# TC37X register map
File version: 1.0.0
CPU: CM4 r0p1, little endian, MPU, FPU, VTOR, 3 interrupt priority bits
Registers are 16-bit, read-write, reset 0x0 unless marked. A register's access mark holds for its fields unless they carry their own. Offsets are from the block's base; [hi:lo] are bit positions; {n}, {i} and the like mark numbered series; 'fields as' and 'values as' point back to an identical list.

## SRC — ce_src
Base 0xF0038000
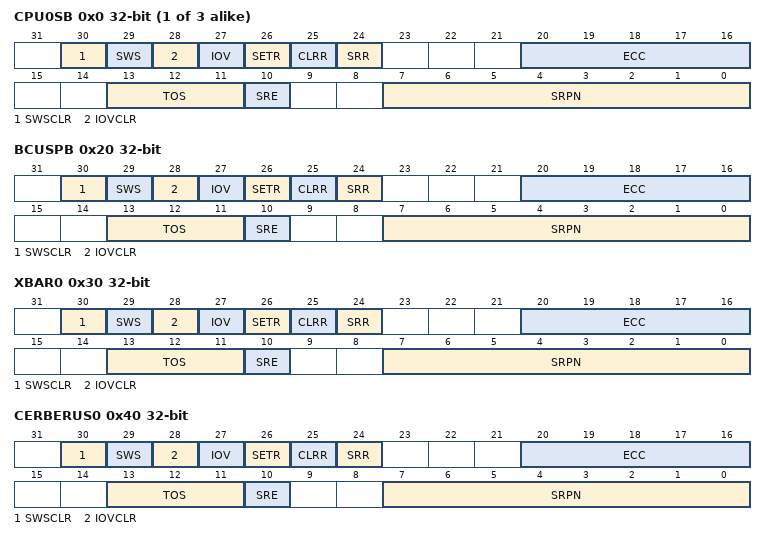
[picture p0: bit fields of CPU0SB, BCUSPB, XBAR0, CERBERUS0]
{0x0+4i} CPU{i}SB 32-bit (i=0..2) — CPU{i} Software Breakpoint Service Request
  [30] SWSCLR wo — SW Sticky Clear Bit
  [29] SWS ro — SW Sticky Bit
  [28] IOVCLR wo — Interrupt Trigger Overflow Clear Bit
  [27] IOV ro — Interrupt Trigger Overflow Bit
  [26] SETR wo — Request Set Bit
  [25] CLRR wo — Request Clear Bit
  [24] SRR ro — Service Request Flag
  [20:16] ECC — Error Correction Code
  [13:11] TOS — Type of Service Control
  [10] SRE — Service Request Enable
  [7:0] SRPN — Service Request Priority Number
0x20 BCUSPB 32-bit — SBCU Service Request (SPB Bus Control Unit)
  fields as CPU0SB
0x30 XBAR0 32-bit — SRI Domain 0 Service Request
  fields as CPU0SB
0x40 CERBERUS0 32-bit — Cerberus Service Request 0
  fields as CPU0SB
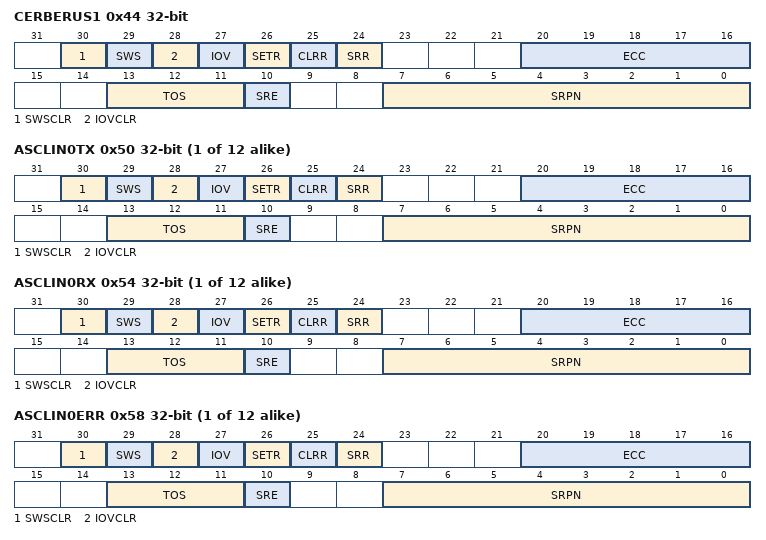
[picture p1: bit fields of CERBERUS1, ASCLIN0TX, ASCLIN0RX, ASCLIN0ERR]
0x44 CERBERUS1 32-bit — Cerberus Service Request 1
  fields as CPU0SB
{0x50+0xC*i} ASCLIN{i}TX 32-bit (i=0..11) — ASCLIN{i} Transmit Service Request
  fields as CPU0SB
{0x54+0xC*i} ASCLIN{i}RX 32-bit (i=0..11) — ASCLIN{i} Receive Service Request
  fields as CPU0SB
{0x58+0xC*i} ASCLIN{i}ERR 32-bit (i=0..11) — ASCLIN{i} Error Service Request
  fields as CPU0SB
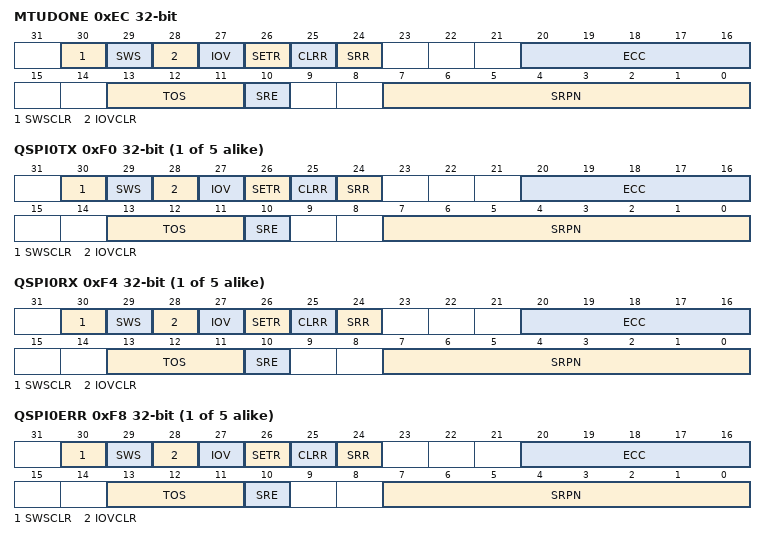
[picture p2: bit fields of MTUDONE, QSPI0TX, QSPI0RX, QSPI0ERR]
0xEC MTUDONE 32-bit — MTU Done Service Request
  fields as CPU0SB
{0xF0+0x14*i} QSPI{i}TX 32-bit (i=0..4) — QSPI{i} Transmit Service Request
  fields as CPU0SB
{0xF4+0x14*i} QSPI{i}RX 32-bit (i=0..4) — QSPI{i} Receive Service Request
  fields as CPU0SB
{0xF8+0x14*i} QSPI{i}ERR 32-bit (i=0..4) — QSPI{i} Error Service Request
  fields as CPU0SB
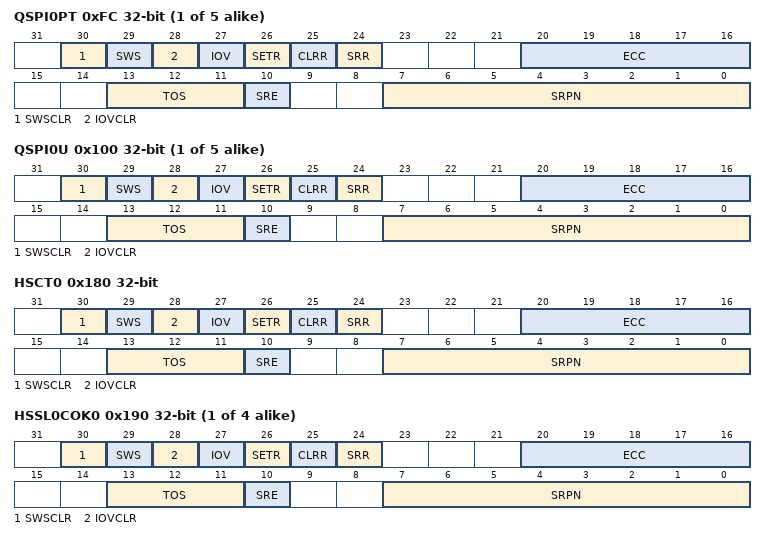
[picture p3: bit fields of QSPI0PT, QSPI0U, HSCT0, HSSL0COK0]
{0xFC+0x14*i} QSPI{i}PT 32-bit (i=0..4) — QSPI{i} Phase Transition Service Request
  fields as CPU0SB
{0x100+0x14*i} QSPI{i}U 32-bit (i=0..4) — QSPI{i} User Defined Service Request
  fields as CPU0SB
0x180 HSCT0 32-bit — HSCT0 Service Request
  fields as CPU0SB
{0x190+0x10*i} HSSL0COK{i} 32-bit (i=0..3) — HSSL0 Channel {i} OK Service Request
  fields as CPU0SB
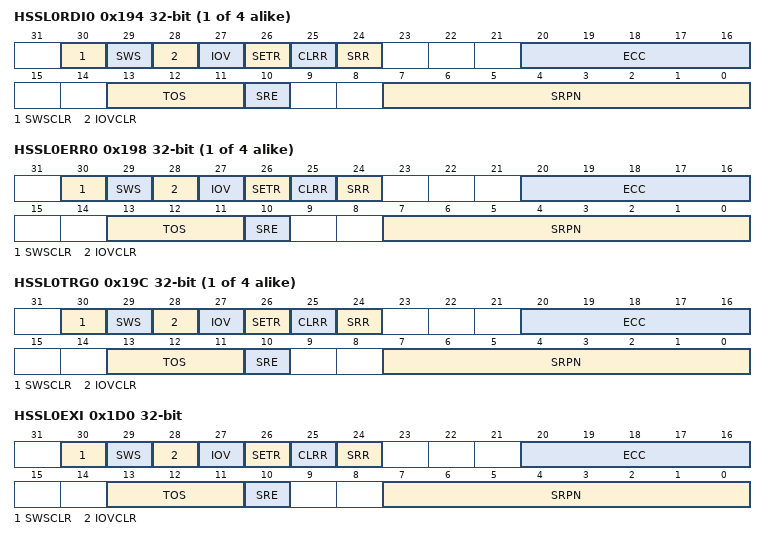
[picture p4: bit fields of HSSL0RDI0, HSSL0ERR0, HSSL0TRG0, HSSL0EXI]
{0x194+0x10*i} HSSL0RDI{i} 32-bit (i=0..3) — HSSL0 Channel {i} Read Data Service Request
  fields as CPU0SB
{0x198+0x10*i} HSSL0ERR{i} 32-bit (i=0..3) — HSSL0 Channel {i} Error Service Request
  fields as CPU0SB
{0x19C+0x10*i} HSSL0TRG{i} 32-bit (i=0..3) — HSSL0 Channel {i} Trigger Interrupt Service Request
  fields as CPU0SB
0x1D0 HSSL0EXI 32-bit — HSSL0 Exception Service Request
  fields as CPU0SB
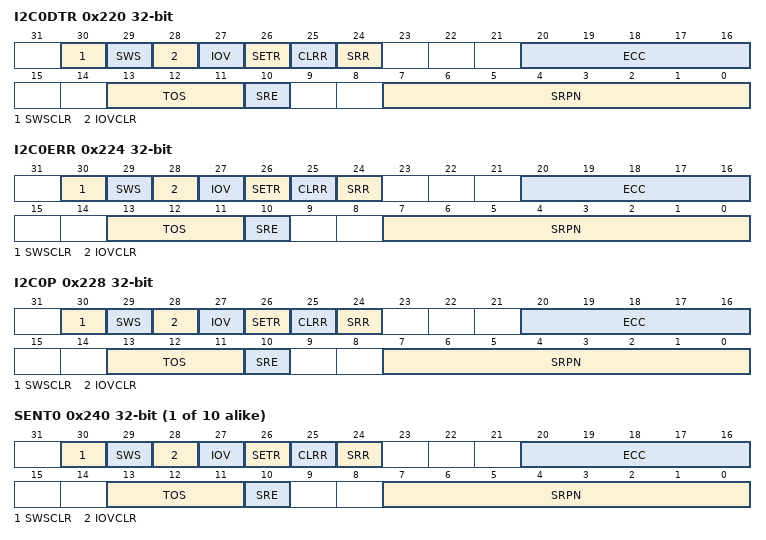
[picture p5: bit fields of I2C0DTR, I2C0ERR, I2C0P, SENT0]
0x220 I2C0DTR 32-bit — I2C0 Data Transfer Request
  fields as CPU0SB
0x224 I2C0ERR 32-bit — I2C0 Error Service Request
  fields as CPU0SB
0x228 I2C0P 32-bit — I2C0 Protocol Service Request
  fields as CPU0SB
{0x240+4i} SENT{i} 32-bit (i=0..9) — SENT TRIG{i} Service Request
  fields as CPU0SB
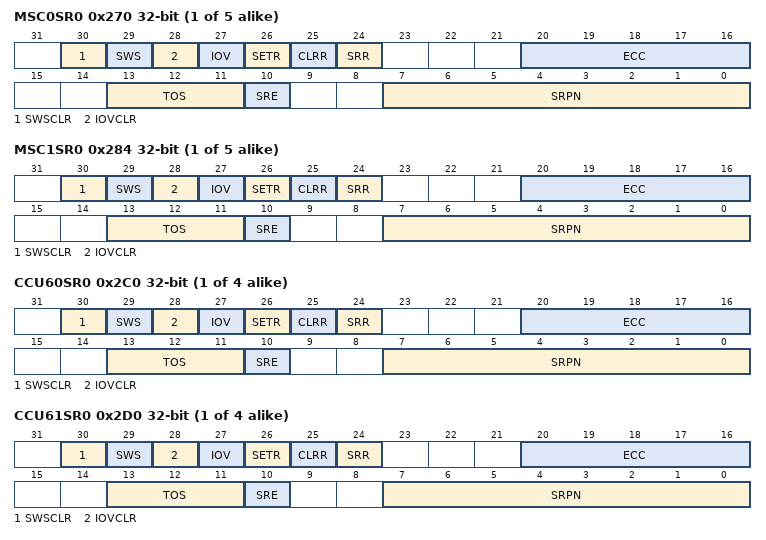
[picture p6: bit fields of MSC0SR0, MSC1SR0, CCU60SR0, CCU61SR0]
{0x270+4i} MSC0SR{i} 32-bit (i=0..4) — MSC0 Service Request {i}
  fields as CPU0SB
{0x284+4i} MSC1SR{i} 32-bit (i=0..4) — MSC1 Service Request {i}
  fields as CPU0SB
{0x2C0+4i} CCU60SR{i} 32-bit (i=0..3) — CCU0 Service Request {i}
  fields as CPU0SB
{0x2D0+4i} CCU61SR{i} 32-bit (i=0..3) — CCU1 Service Request {i}
  fields as CPU0SB
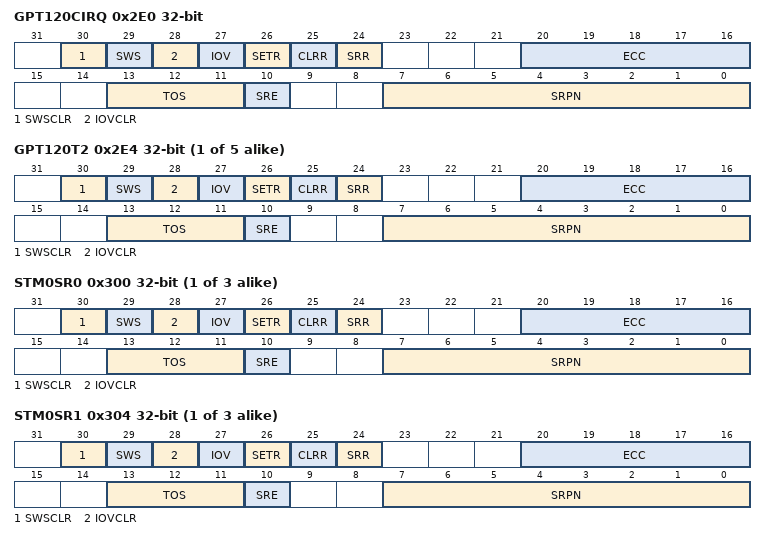
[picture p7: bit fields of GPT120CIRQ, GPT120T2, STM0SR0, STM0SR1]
0x2E0 GPT120CIRQ 32-bit — GPT120 CAPREL Service Request
  fields as CPU0SB
{0x2DC+4i} GPT120T{i} 32-bit (i=2..6) — GPT120 Timer {i} Service Request
  fields as CPU0SB
{0x300+8i} STM{i}SR0 32-bit (i=0..2) — System Timer {i} Service Request 0
  fields as CPU0SB
{0x304+8i} STM{i}SR1 32-bit (i=0..2) — System Timer {i} Service Request 1
  fields as CPU0SB
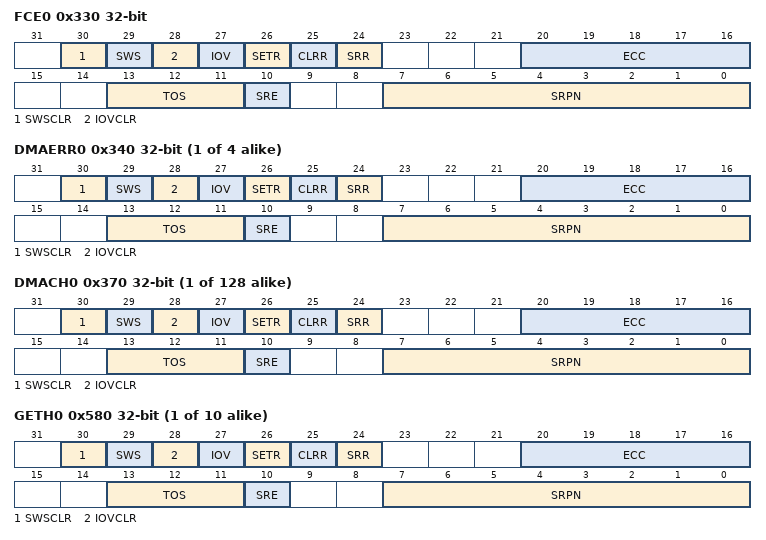
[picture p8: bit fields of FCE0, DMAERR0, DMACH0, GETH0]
0x330 FCE0 32-bit — FCE0 Error Service Request
  fields as CPU0SB
{0x340+4i} DMAERR{i} 32-bit (i=0..3) — DMA Error Service Request {i}
  fields as CPU0SB
{0x370+4i} DMACH{i} 32-bit (i=0..127) — DMA Channel {i} Service Request
  fields as CPU0SB
{0x580+4i} GETH{i} 32-bit (i=0..9) — GETH Service Request {i}
  fields as CPU0SB
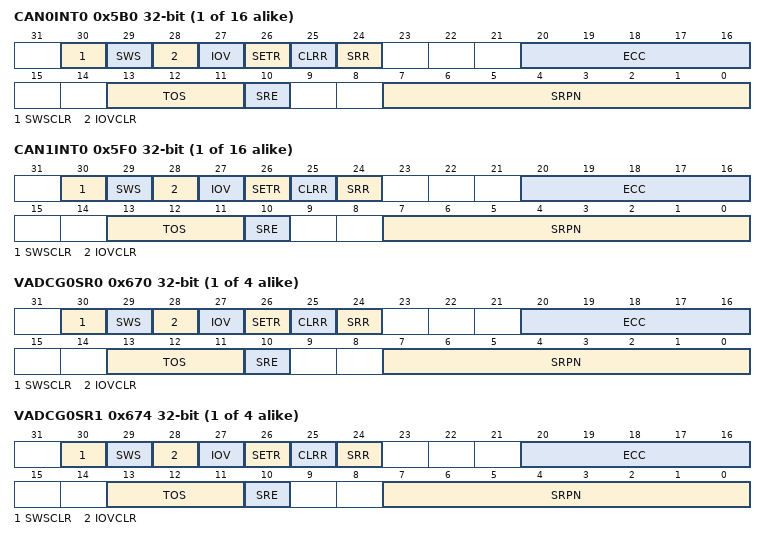
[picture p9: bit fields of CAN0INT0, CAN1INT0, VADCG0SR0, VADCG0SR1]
{0x5B0+4i} CAN0INT{i} 32-bit (i=0..15) — CAN0 Service Request {i}
  fields as CPU0SB
{0x5F0+4i} CAN1INT{i} 32-bit (i=0..15) — CAN1 Service Request {i}
  fields as CPU0SB
{0x670+0x10*i} VADCG{i}SR0 32-bit (i=0..3) — EVADC Group {i} Service Request 0
  fields as CPU0SB
{0x674+0x10*i} VADCG{i}SR1 32-bit (i=0..3) — EVADC Group {i} Service Request 1
  fields as CPU0SB
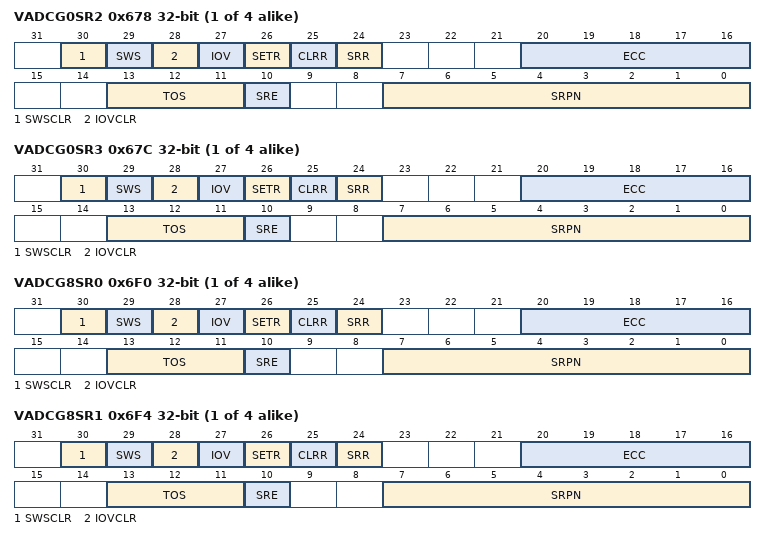
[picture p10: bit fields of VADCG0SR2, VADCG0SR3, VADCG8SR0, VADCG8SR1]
{0x678+0x10*i} VADCG{i}SR2 32-bit (i=0..3) — EVADC Group {i} Service Request 2
  fields as CPU0SB
{0x67C+0x10*i} VADCG{i}SR3 32-bit (i=0..3) — EVADC Group {i} Service Request 3
  fields as CPU0SB
{0x670+0x10*i} VADCG{i}SR0 32-bit (i=8..11) — EVADC Group {i} Service Request 0
  fields as CPU0SB
{0x674+0x10*i} VADCG{i}SR1 32-bit (i=8..11) — EVADC Group {i} Service Request 1
  fields as CPU0SB
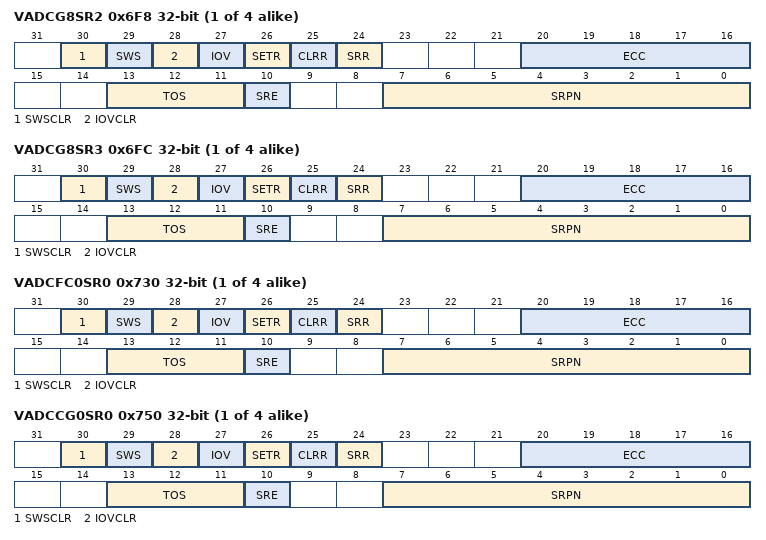
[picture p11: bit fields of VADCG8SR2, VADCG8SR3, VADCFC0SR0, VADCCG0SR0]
{0x678+0x10*i} VADCG{i}SR2 32-bit (i=8..11) — EVADC Group {i} Service Request 2
  fields as CPU0SB
{0x67C+0x10*i} VADCG{i}SR3 32-bit (i=8..11) — EVADC Group {i} Service Request 3
  fields as CPU0SB
{0x730+4i} VADCFC{i}SR0 32-bit (i=0..3) — EVADC Fast Compare {i} Service Request SR0
  fields as CPU0SB
{0x750+4i} VADCCG0SR{i} 32-bit (i=0..3) — EVADC Common Group 0 Service Request {i}
  fields as CPU0SB
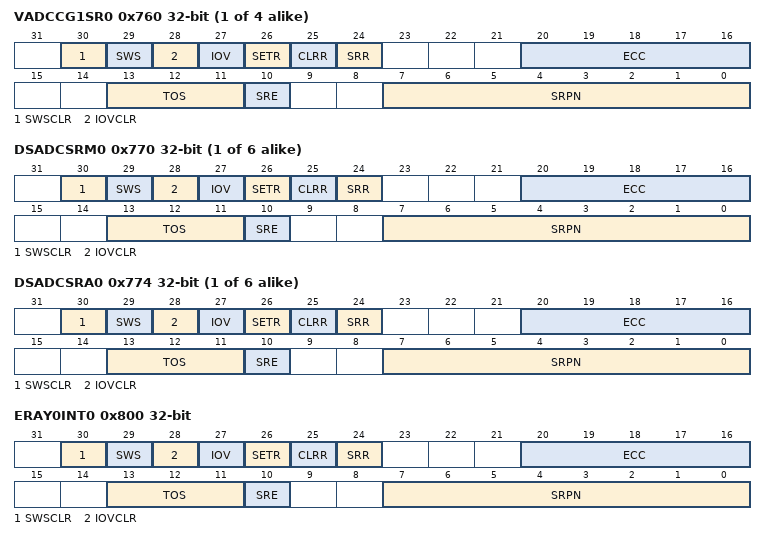
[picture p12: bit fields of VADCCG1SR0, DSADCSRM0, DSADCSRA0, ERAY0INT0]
{0x760+4i} VADCCG1SR{i} 32-bit (i=0..3) — EVADC Common Group 1 Service Request {i}
  fields as CPU0SB
{0x770+8i} DSADCSRM{i} 32-bit (i=0..5) — DSADC SRM{i} Service Request
  fields as CPU0SB
{0x774+8i} DSADCSRA{i} 32-bit (i=0..5) — DSADC SRA{i} Service Request
  fields as CPU0SB
0x800 ERAY0INT0 32-bit — E-RAY 0 Service Request 0
  fields as CPU0SB
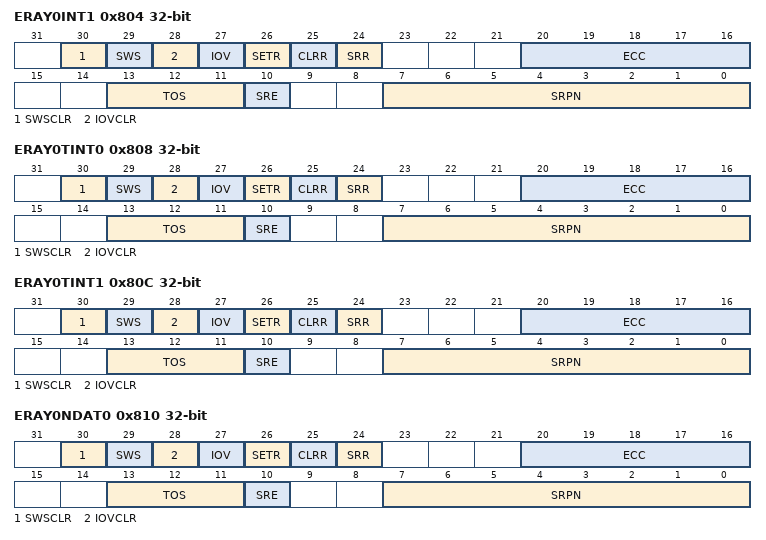
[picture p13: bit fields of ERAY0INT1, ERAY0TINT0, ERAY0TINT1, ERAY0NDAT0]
0x804 ERAY0INT1 32-bit — E-RAY 0 Service Request 1
  fields as CPU0SB
0x808 ERAY0TINT0 32-bit — E-RAY 0 Timer Interrupt 0 Service Request
  fields as CPU0SB
0x80C ERAY0TINT1 32-bit — E-RAY 0 Timer Interrupt 1 Service Request
  fields as CPU0SB
0x810 ERAY0NDAT0 32-bit — E-RAY 0 New Data 0 Service Request
  fields as CPU0SB
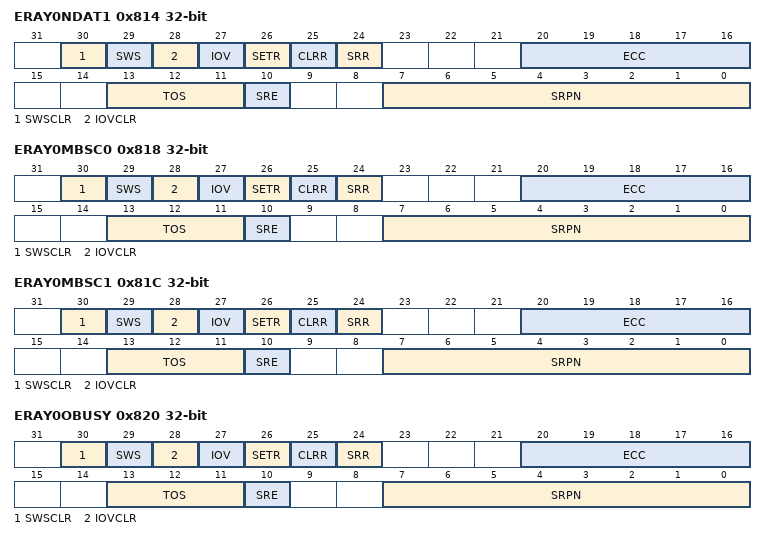
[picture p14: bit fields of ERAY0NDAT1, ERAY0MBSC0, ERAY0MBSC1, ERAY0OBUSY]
0x814 ERAY0NDAT1 32-bit — E-RAY 0 New Data 1 Service Request
  fields as CPU0SB
0x818 ERAY0MBSC0 32-bit — E-RAY 0 Message Buffer Status Changed 0 Service Request
  fields as CPU0SB
0x81C ERAY0MBSC1 32-bit — E-RAY 0 Message Buffer Status Changed 1 Service Request
  fields as CPU0SB
0x820 ERAY0OBUSY 32-bit — E-RAY 0 Output Buffer Busy
  fields as CPU0SB
0x824 ERAY0IBUSY 32-bit — E-RAY 0 Input Buffer Busy
  fields as CPU0SB
0x860 DMUHOST 32-bit — DMU Host Service Request
  fields as CPU0SB
0x864 DMUFSI 32-bit — DMU FSI Service Request
  fields as CPU0SB
0x870 HSM0 32-bit — HSM Service Request 0
  fields as CPU0SB
0x874 HSM1 32-bit — HSM Service Request 1
  fields as CPU0SB
{0x880+4i} SCUERU{i} 32-bit (i=0..3) — SCU ERU Service Request {i}
  fields as CPU0SB
0x8AC PMSDTS 32-bit — PMS DTS Service Request
  fields as CPU0SB
{0x8B0+4i} PMS{i} 32-bit (i=0..3) — Power Management System Service Request {i}
  fields as CPU0SB
0x8C0 SCR 32-bit — Stand By Controller Service Request
  fields as CPU0SB
{0x8D0+4i} SMU{i} 32-bit (i=0..2) — SMU Service Request {i}
  fields as CPU0SB
{0x818+4i} PSI{i} 32-bit (i=50..57) — PSI5 Service Request {i-50}
  fields as CPU0SB
0x910 DAM0LI0 32-bit — DAM0 Limit 0 Service Request
  fields as CPU0SB
0x914 DAM0RI0 32-bit — DAM0 Ready 0 Service Reques
  fields as CPU0SB
0x918 DAM0LI1 32-bit — DAM0 Limit 1 Service Request
  fields as CPU0SB
0x91C DAM0RI1 32-bit — DAM0 Ready 1 Service Request
  fields as CPU0SB
0x920 DAM0DR 32-bit — DAM0 DMA Ready Service Request
  fields as CPU0SB
0x924 DAM0ERR 32-bit — DAM0 Error Service Request
  fields as CPU0SB
{0x950+4i} PSI5S{i} 32-bit (i=0..7) — PSI5-S Service Request {i}
  fields as CPU0SB
{0x990+4i} GPSR{i:02} 32-bit (i=0..7) — General Purpose Group 0 Service Request {i}
  fields as CPU0SB
{0x988+4i} GPSR{i} 32-bit (i=10..17) — General Purpose Group 1 Service Request {i-10}
  fields as CPU0SB
{0x980+4i} GPSR{i} 32-bit (i=20..27) — General Purpose Group 2 Service Request {i-20}
  fields as CPU0SB
0xA70 GTMAEIIRQ 32-bit — AEI Shared Service Request
  fields as CPU0SB
{0xA74+4i} GTMARUIRQ{i} 32-bit (i=0..2) — ARU Shared Service Request {i}
  fields as CPU0SB
0xA80 GTMBRCIRQ 32-bit — BRC Shared Service Request
  fields as CPU0SB
0xA84 GTMCMPIRQ 32-bit — CMP Shared Service Request
  fields as CPU0SB
0xA88 GTMSPE0IRQ 32-bit — SPE0 Shared Service Request
  fields as CPU0SB
0xA8C GTMSPE1IRQ 32-bit — SPE1 Shared Service Request
  fields as CPU0SB
{0xAA0+4i} GTMPSM{i:02} 32-bit (i=0..7) — PSM0 Shared Service Request {i}
  fields as CPU0SB
{0xB00+4i} GTMDPLL{i} 32-bit (i=0..26) — DPLL Service Request {i}
  fields as CPU0SB
0xB70 GTMERR 32-bit — Error Service Request
  fields as CPU0SB
{0xB90+4i} GTMTIM{i:02} 32-bit (i=0..7) — TIM0 Shared Service Request {i}
  fields as CPU0SB
{0xB88+4i} GTMTIM{i} 32-bit (i=10..17) — TIM1 Shared Service Request {i-10}
  fields as CPU0SB
{0xB80+4i} GTMTIM{i} 32-bit (i=20..27) — TIM2 Shared Service Request {i-20}
  fields as CPU0SB
{0xB78+4i} GTMTIM{i} 32-bit (i=30..37) — TIM3 Shared Service Request {i-30}
  fields as CPU0SB
{0xB70+4i} GTMTIM{i} 32-bit (i=40..47) — TIM4 Shared Service Request {i-40}
  fields as CPU0SB
{0xB68+4i} GTMTIM{i} 32-bit (i=50..57) — TIM5 Shared Service Request {i-50}
  fields as CPU0SB
{0xCB0+4i} GTMMCS{i:02} 32-bit (i=0..7) — MCS0 Shared Service Request {i}
  fields as CPU0SB
{0xCA8+4i} GTMMCS{i} 32-bit (i=10..17) — MCS1 Shared Service Request {i-10}
  fields as CPU0SB
{0xCA0+4i} GTMMCS{i} 32-bit (i=20..27) — MCS2 Shared Service Request {i-20}
  fields as CPU0SB
{0xC98+4i} GTMMCS{i} 32-bit (i=30..37) — MCS3 Shared Service Request {i-30}
  fields as CPU0SB
{0xC90+4i} GTMMCS{i} 32-bit (i=40..47) — MCS4 Shared Service Request {i-40}
  fields as CPU0SB
{0xE10+4i} GTMTOM{i:02} 32-bit (i=0..7) — TOM0 Shared Service Request {i}
  fields as CPU0SB
{0xE08+4i} GTMTOM{i} 32-bit (i=10..17) — TOM1 Shared Service Request {i-10}
  fields as CPU0SB
{0xE00+4i} GTMTOM{i} 32-bit (i=20..27) — TOM2 Shared Service Request {i-20}
  fields as CPU0SB
{0xEF0+4i} GTMATOM{i:02} 32-bit (i=0..3) — ATOM0 Shared Service Request {i}
  fields as CPU0SB
{0xED8+4i} GTMATOM{i} 32-bit (i=10..13) — ATOM1 Shared Service Request {i-10}
  fields as CPU0SB
{0xEC0+4i} GTMATOM{i} 32-bit (i=20..23) — ATOM2 Shared Service Request {i-20}
  fields as CPU0SB
{0xEA8+4i} GTMATOM{i} 32-bit (i=30..33) — ATOM3 Shared Service Request {i-30}
  fields as CPU0SB
{0xE90+4i} GTMATOM{i} 32-bit (i=40..43) — ATOM4 Shared Service Request {i-40}
  fields as CPU0SB
{0xE78+4i} GTMATOM{i} 32-bit (i=50..53) — ATOM5 Shared Service Request {i-50}
  fields as CPU0SB
{0xFD0+4i} GTMMCSW{i} 32-bit (i=0..9) — GTM Multi Channel Sequencer Service Request {i}
  fields as CPU0SB
